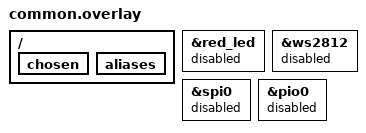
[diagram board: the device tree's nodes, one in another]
/ {
    chosen {
        /delete-property/ zephyr,console;
        /delete-property/ zephyr,shell-uart;
    };

    aliases {
        /delete-property/ led-strip;
    };
};

&red_led {
    status = "disabled";
};

&ws2812 {
    status = "disabled";
};

&spi0 {
    status = "disabled";
};

&pio0 {
    status = "disabled";
};
